# ESP32-H2 register map
Vendor: ESPRESSIF SYSTEMS (SHANGHAI) CO., LTD.; Series: ESP32 H-Series; File version: 12
CPU: RV32IMAC r0p0, little endian, no MPU, no FPU, 0 interrupt priority bits
Address unit: 32 bits
Registers are 32-bit, read-write, reset 0x0 unless marked. A register's access mark holds for its fields unless they carry their own. Offsets are from the block's base; [hi:lo] are bit positions.

## MEM_MONITOR — MEM_MONITOR Peripheral
Base 0x60092000
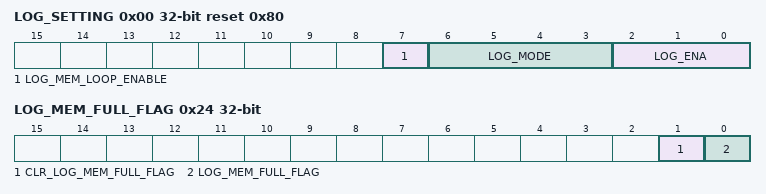
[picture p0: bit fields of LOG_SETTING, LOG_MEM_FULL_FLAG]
0x00 LOG_SETTING reset 0x80 — log config regsiter
  [7] LOG_MEM_LOOP_ENABLE — Set 1 enable mem_loop, it will loop write at the range of MEM_START and MEM_END
  [6:3] LOG_MODE — This field must be onehot. 4'b0001 : WR monitor, 4'b0010: WORD monitor, 4'b0100: HALFWORD monitor, 4'b1000: BYTE monitor.
  [2:0] LOG_ENA — enable bus log. BIT0: hp-cpu, BIT1: lp-cpu, BIT2: DMA.823 don't support lp-cpu
0x04 LOG_CHECK_DATA — check data regsiter
  [31:0] LOG_CHECK_DATA — The special check data, when write this special data, it will trigger logging.
0x08 LOG_DATA_MASK — check data mask register
  [3:0] LOG_DATA_MASK — byte mask enable, BIT0 mask the first byte of MEM_MONITOR_LOG_CHECK_DATA, and BIT1 mask second byte, and so on.
0x0C LOG_MIN — log boundary regsiter
  [31:0] LOG_MIN — the min address of log range
0x10 LOG_MAX — log boundary regsiter
  [31:0] LOG_MAX — the max address of log range
0x14 LOG_MEM_START — log message store range register
  [31:0] LOG_MEM_START — the start address of writing logging message
0x18 LOG_MEM_END — log message store range register
  [31:0] LOG_MEM_END — the end address of writing logging message
0x1C LOG_MEM_CURRENT_ADDR ro — current writing address.
  [31:0] LOG_MEM_CURRENT_ADDR — means next writing address
0x20 LOG_MEM_ADDR_UPDATE wo — writing address update
  [0] LOG_MEM_ADDR_UPDATE — Set 1 to updata MEM_MONITOR_LOG_MEM_CURRENT_ADDR, when set 1, MEM_MONITOR_LOG_MEM_CURRENT_ADDR will update to MEM_MONITOR_LOG_MEM_START
0x24 LOG_MEM_FULL_FLAG access per field — full flag status register
  [1] CLR_LOG_MEM_FULL_FLAG wo — Set 1 to clr MEM_MONITOR_LOG_MEM_FULL_FLAG
  [0] LOG_MEM_FULL_FLAG ro — 1 means memory write loop at least one time at the range of MEM_START and MEM_END
0x28 CLOCK_GATE — clock gate force on register
  [0] CLK_EN — Set 1 to force on the clk of mem_monitor register
0x3FC DATE reset 0x2202140 — version register
  [27:0] DATE

## MODEM_LPCON — MODEM_LPCON Peripheral
Base 0x600AD000
0x00 TEST_CONF
  [0] CLK_EN
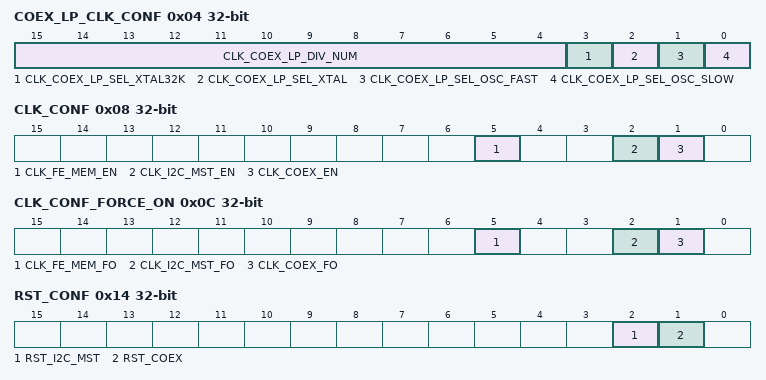
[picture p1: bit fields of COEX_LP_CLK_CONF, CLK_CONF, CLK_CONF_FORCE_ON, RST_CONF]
0x04 COEX_LP_CLK_CONF
  [15:4] CLK_COEX_LP_DIV_NUM, [3] CLK_COEX_LP_SEL_XTAL32K, [2] CLK_COEX_LP_SEL_XTAL, [1] CLK_COEX_LP_SEL_OSC_FAST, [0] CLK_COEX_LP_SEL_OSC_SLOW
0x08 CLK_CONF
  [5] CLK_FE_MEM_EN, [2] CLK_I2C_MST_EN, [1] CLK_COEX_EN
0x0C CLK_CONF_FORCE_ON
  [5] CLK_FE_MEM_FO, [2] CLK_I2C_MST_FO, [1] CLK_COEX_FO
0x10 TICK_CONF reset 0x1F
  [5:0] PWR_TICK_TARGET
0x14 RST_CONF wo
  [2] RST_I2C_MST, [1] RST_COEX
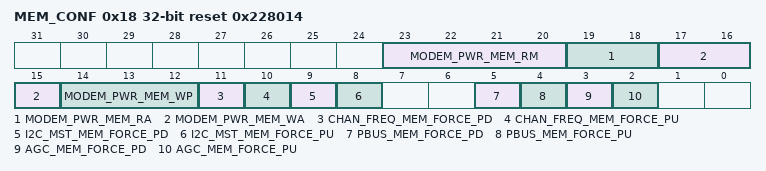
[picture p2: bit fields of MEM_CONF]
0x18 MEM_CONF reset 0x228014
  [23:20] MODEM_PWR_MEM_RM, [19:18] MODEM_PWR_MEM_RA, [17:15] MODEM_PWR_MEM_WA, [14:12] MODEM_PWR_MEM_WP, [11] CHAN_FREQ_MEM_FORCE_PD, [10] CHAN_FREQ_MEM_FORCE_PU, [9] I2C_MST_MEM_FORCE_PD, [8] I2C_MST_MEM_FORCE_PU, [5] PBUS_MEM_FORCE_PD, [4] PBUS_MEM_FORCE_PU, [3] AGC_MEM_FORCE_PD, [2] AGC_MEM_FORCE_PU
0x1C DATE reset 0x2209280
  [27:0] DATE

## MODEM_SYSCON — MODEM_SYSCON Peripheral
Base 0x600A5400
0x00 TEST_CONF
  [0] CLK_EN
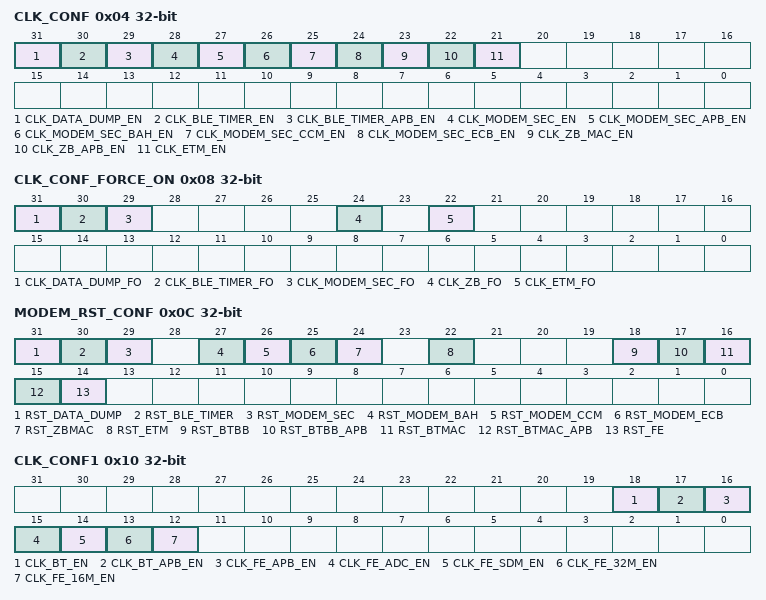
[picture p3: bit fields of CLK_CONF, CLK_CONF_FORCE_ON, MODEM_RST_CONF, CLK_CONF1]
0x04 CLK_CONF
  [31] CLK_DATA_DUMP_EN, [30] CLK_BLE_TIMER_EN, [29] CLK_BLE_TIMER_APB_EN, [28] CLK_MODEM_SEC_EN, [27] CLK_MODEM_SEC_APB_EN, [26] CLK_MODEM_SEC_BAH_EN, [25] CLK_MODEM_SEC_CCM_EN, [24] CLK_MODEM_SEC_ECB_EN, [23] CLK_ZB_MAC_EN, [22] CLK_ZB_APB_EN, [21] CLK_ETM_EN
0x08 CLK_CONF_FORCE_ON
  [31] CLK_DATA_DUMP_FO, [30] CLK_BLE_TIMER_FO, [29] CLK_MODEM_SEC_FO, [24] CLK_ZB_FO, [22] CLK_ETM_FO
0x0C MODEM_RST_CONF
  [31] RST_DATA_DUMP, [30] RST_BLE_TIMER, [29] RST_MODEM_SEC, [27] RST_MODEM_BAH, [26] RST_MODEM_CCM, [25] RST_MODEM_ECB, [24] RST_ZBMAC, [22] RST_ETM, [18] RST_BTBB, [17] RST_BTBB_APB, [16] RST_BTMAC, [15] RST_BTMAC_APB, [14] RST_FE
0x10 CLK_CONF1
  [18] CLK_BT_EN, [17] CLK_BT_APB_EN, [16] CLK_FE_APB_EN, [15] CLK_FE_ADC_EN, [14] CLK_FE_SDM_EN, [13] CLK_FE_32M_EN, [12] CLK_FE_16M_EN
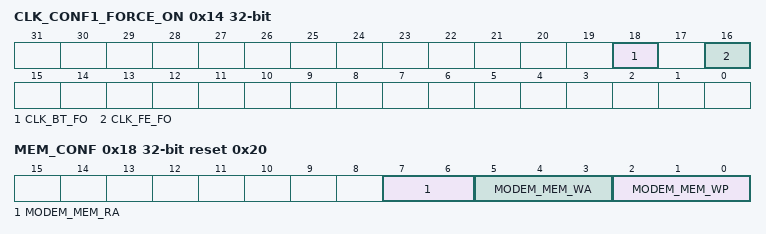
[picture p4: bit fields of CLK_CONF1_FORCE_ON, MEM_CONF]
0x14 CLK_CONF1_FORCE_ON
  [18] CLK_BT_FO, [16] CLK_FE_FO
0x18 MEM_CONF reset 0x20
  [7:6] MODEM_MEM_RA, [5:3] MODEM_MEM_WA, [2:0] MODEM_MEM_WP
0x1C DATE reset 0x2208300
  [27:0] DATE
